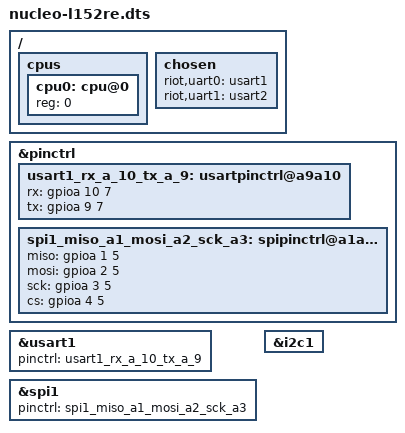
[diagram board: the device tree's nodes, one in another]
/dts-v1/;
#include "stm32l152re.dtsi"

/ {
    cpus {
        #address-cells = <1>;
        #size-cells = <0>;
        cpu0: cpu@0 {
            reg = <0>;
        };
    };

    chosen {
        riot,uart0 = <&usart1>;
        riot,uart1 = <&usart2>;
    };
};

&pinctrl {
    usart1_rx_a_10_tx_a_9: usartpinctrl@a9a10 {
        rx = <&gpioa 10 7>;
        tx = <&gpioa 9 7>;
    };
};

&usart1 {
    status = "okay";
    pinctrl = <&usart1_rx_a_10_tx_a_9>;
};

&pinctrl {
    spi1_miso_a1_mosi_a2_sck_a3: spipinctrl@a1a2a3 {
        miso = <&gpioa 1 5>;
        mosi = <&gpioa 2 5>;
        sck = <&gpioa 3 5>;
        cs = <&gpioa 4 5>;
    };
};
&spi1 {
    status = "okay";
    pinctrl = <&spi1_miso_a1_mosi_a2_sck_a3>;
};

&i2c1 {
    status = "okay";
};
